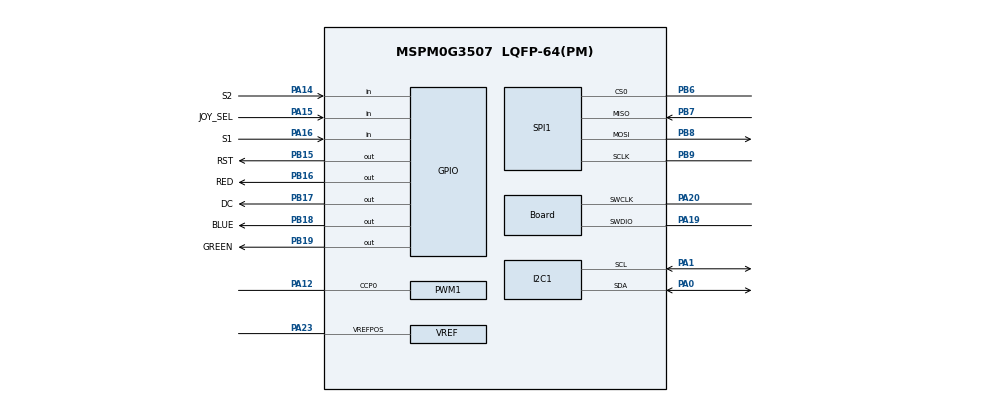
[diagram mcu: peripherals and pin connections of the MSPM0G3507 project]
/**
 * Motion Music Studio - Simple Clock (NO CRASH)
 */
//@cliArgs --device "MSPM0G350X" --package "LQFP-64(PM)" --part "Default"
//@v2CliArgs --device "MSPM0G3507" --package "LQFP-64(PM)"

const ADC12 = scripting.addModule("/ti/driverlib/ADC12", {}, false);
const ADC121 = ADC12.addInstance();
const ADC122 = ADC12.addInstance();
const Board = scripting.addModule("/ti/driverlib/Board");
const GPIO = scripting.addModule("/ti/driverlib/GPIO", {}, false);
const GPIO1 = GPIO.addInstance();
const GPIO2 = GPIO.addInstance();
const GPIO3 = GPIO.addInstance();
const I2C = scripting.addModule("/ti/driverlib/I2C", {}, false);
const I2C1 = I2C.addInstance();
const PWM = scripting.addModule("/ti/driverlib/PWM", {}, false);
const PWM1 = PWM.addInstance();
const SPI = scripting.addModule("/ti/driverlib/SPI", {}, false);
const SPI1 = SPI.addInstance();
const SYSCTL = scripting.addModule("/ti/driverlib/SYSCTL");
const TIMER = scripting.addModule("/ti/driverlib/TIMER", {}, false);
const TIMER1 = TIMER.addInstance();
const VREF = scripting.addModule("/ti/driverlib/VREF");
const ProjectConfig = scripting.addModule("/ti/project_config/ProjectConfig");

ADC121.$name = "ADC_MIC_JOY";
ADC121.sampClkDiv = "DL_ADC12_CLOCK_DIVIDE_4";
ADC121.sampleTime0 = "125 us";
ADC121.samplingOperationMode = "sequence";
ADC121.repeatMode = true;
ADC121.endAdd = 2;
ADC121.enabledInterrupts = ["DL_ADC12_INTERRUPT_MEM0_RESULT_LOADED","DL_ADC12_INTERRUPT_MEM1_RESULT_LOADED","DL_ADC12_INTERRUPT_MEM2_RESULT_LOADED"];
ADC121.enabledEvents = ["DL_ADC12_EVENT_MEM0_RESULT_LOADED"];
ADC121.pubChanID = 2;
ADC121.subChanID = 2;
ADC121.adcMem0_name = "MIC";
ADC121.adcMem0chansel = "DL_ADC12_INPUT_CHAN_2";
ADC121.adcMem1_name = "JOY_Y";
ADC121.adcMem1chansel = "DL_ADC12_INPUT_CHAN_1";
ADC121.adcMem2_name = "JOY_X";
ADC121.peripheral.$assign = "ADC0";
ADC121.peripheral.adcPin0.$assign = "PA27";
ADC121.peripheral.adcPin1.$assign = "PA26";
ADC121.peripheral.adcPin2.$assign = "PA25";

ADC122.$name = "ADC_ACCEL";
ADC122.sampClkDiv = "DL_ADC12_CLOCK_DIVIDE_8";
ADC122.sampleTime0 = "125 us";
ADC122.samplingOperationMode = "sequence";
ADC122.repeatMode = true;
ADC122.trigSrc = "DL_ADC12_TRIG_SRC_EVENT";
ADC122.endAdd = 2;
ADC122.enabledInterrupts = ["DL_ADC12_INTERRUPT_MEM0_RESULT_LOADED","DL_ADC12_INTERRUPT_MEM1_RESULT_LOADED","DL_ADC12_INTERRUPT_MEM2_RESULT_LOADED"];
ADC122.enabledEvents = ["DL_ADC12_EVENT_MEM0_RESULT_LOADED"];
ADC122.pubChanID = 1;
ADC122.subChanID = 1;
ADC122.adcMem0_name = "ACCEL_X";
ADC122.adcMem0chansel = "DL_ADC12_INPUT_CHAN_2";
ADC122.adcMem0vref = "VREF";
ADC122.adcMem1_name = "ACCEL_Y";
ADC122.adcMem1chansel = "DL_ADC12_INPUT_CHAN_3";
ADC122.adcMem1vref = "VREF";
ADC122.adcMem2_name = "ACCEL_Z";
ADC122.adcMem2chansel = "DL_ADC12_INPUT_CHAN_7";
ADC122.adcMem2vref = "VREF";
ADC122.peripheral.$assign = "ADC1";
ADC122.peripheral.adcPin2.$assign = "PA17";
ADC122.peripheral.adcPin3.$assign = "PA18";
ADC122.peripheral.adcPin7.$assign = "PA21";

Board.peripheral.$assign = "DEBUGSS";
Board.peripheral.swclkPin.$assign = "PA20";
Board.peripheral.swdioPin.$assign = "PA19";

GPIO1.$name = "GPIO_BUTTONS";
GPIO1.port = "PORTA";
GPIO1.associatedPins.create(3);
GPIO1.associatedPins[0].$name = "S1";
GPIO1.associatedPins[0].direction = "INPUT";
GPIO1.associatedPins[0].internalResistor = "PULL_UP";
GPIO1.associatedPins[0].interruptEn = true;
GPIO1.associatedPins[0].polarity = "FALL";
GPIO1.associatedPins[0].pin.$assign = "PA16";
GPIO1.associatedPins[1].$name = "S2";
GPIO1.associatedPins[1].direction = "INPUT";
GPIO1.associatedPins[1].internalResistor = "PULL_UP";
GPIO1.associatedPins[1].interruptEn = true;
GPIO1.associatedPins[1].polarity = "FALL";
GPIO1.associatedPins[1].pin.$assign = "PA14";
GPIO1.associatedPins[2].$name = "JOY_SEL";
GPIO1.associatedPins[2].direction = "INPUT";
GPIO1.associatedPins[2].internalResistor = "PULL_UP";
GPIO1.associatedPins[2].interruptEn = true;
GPIO1.associatedPins[2].polarity = "FALL";
GPIO1.associatedPins[2].pin.$assign = "PA15";

GPIO2.$name = "GPIO_RGB";
GPIO2.port = "PORTB";
GPIO2.associatedPins.create(3);
GPIO2.associatedPins[0].$name = "RED";
GPIO2.associatedPins[0].initialValue = "SET";
GPIO2.associatedPins[0].pin.$assign = "PB16";
GPIO2.associatedPins[1].$name = "GREEN";
GPIO2.associatedPins[1].initialValue = "SET";
GPIO2.associatedPins[1].pin.$assign = "PB19";
GPIO2.associatedPins[2].$name = "BLUE";
GPIO2.associatedPins[2].initialValue = "SET";
GPIO2.associatedPins[2].pin.$assign = "PB18";

GPIO3.$name = "GPIO_LCD";
GPIO3.port = "PORTB";
GPIO3.associatedPins.create(2);
GPIO3.associatedPins[0].$name = "RST";
GPIO3.associatedPins[0].pin.$assign = "PB15";
GPIO3.associatedPins[1].$name = "DC";
GPIO3.associatedPins[1].pin.$assign = "PB17";

I2C1.$name = "I2C_SENSORS";
I2C1.basicEnableController = true;
I2C1.peripheral.$assign = "I2C0";
I2C1.peripheral.sdaPin.$assign = "PA0";
I2C1.peripheral.sclPin.$assign = "PA1";

PWM1.$name = "PWM_AUDIO";
PWM1.pwmMode = "EDGE_ALIGN_UP";
PWM1.ccIndex = [0];
PWM1.timerStartTimer = true;
PWM1.timerCount = 4095;
PWM1.PWM_CHANNEL_0.$name = "ti_driverlib_pwm_PWMTimerCC0";
PWM1.PWM_CHANNEL_0.dutyCycle = 50;
PWM1.peripheral.$assign = "TIMG0";
PWM1.peripheral.ccp0Pin.$assign = "PA12";

SPI1.$name = "SPI_LCD";
SPI1.targetBitRate = 10000000;
SPI1.peripheral.$assign = "SPI1";
SPI1.peripheral.sclkPin.$assign = "PB9";
SPI1.peripheral.mosiPin.$assign = "PB8";
SPI1.peripheral.misoPin.$assign = "PB7";
SPI1.peripheral.cs0Pin.$assign = "PB6";

TIMER1.$name = "TIMER_SAMPLE";
TIMER1.timerPeriod = "50 us";
TIMER1.interrupts = ["ZERO"];
TIMER1.interruptPriority = "1";
TIMER1.timerStartTimer = true;
TIMER1.timerMode = "PERIODIC";
TIMER1.peripheral.$assign = "TIMG7";

VREF.basicIntVolt = "DL_VREF_BUFCONFIG_OUTPUT_2_5V";
VREF.checkVREFReady = true;
VREF.peripheral.$assign = "VREF";
VREF.peripheral.vrefPosPin.$assign = "PA23";

SYSCTL.forceDefaultClkConfig = true;
SYSCTL.clockTreeEn = true;
SYSCTL.peripheral.$assign = "SYSCTL";

ProjectConfig.genLibDrivers = true;
ProjectConfig.genLibCMSIS = true;
